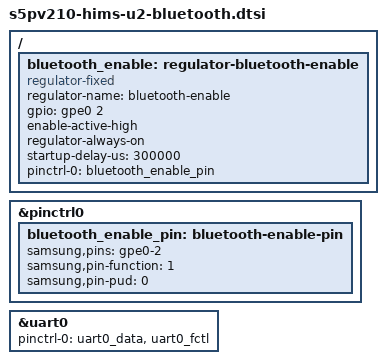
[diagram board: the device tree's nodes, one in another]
// SPDX-License-Identifier: GPL-2.0-only
/* Factory BuiltIn transport: CSR BCSP, COM1/UART0; transport overrides registry baud.
 * HOUSE selector 6 sets GPE0[2] and waits 300 ms. Keep power enabled;
 * suspend, shared factory handshakes and power cycling are not qualified.
 */
/ {
    bluetooth_enable: regulator-bluetooth-enable {
        compatible = "regulator-fixed";
        regulator-name = "bluetooth-enable";
        gpio = <&gpe0 2 GPIO_ACTIVE_HIGH>;
        enable-active-high;
        regulator-always-on;
        startup-delay-us = <300000>;
        pinctrl-names = "default";
        pinctrl-0 = <&bluetooth_enable_pin>;
    };
};
&pinctrl0 {
    bluetooth_enable_pin: bluetooth-enable-pin {
        samsung,pins = "gpe0-2";
        samsung,pin-function = <1>;
        samsung,pin-pud = <0>;
    };
};
&uart0 {
    pinctrl-names = "default";
    pinctrl-0 = <&uart0_data &uart0_fctl>;
    status = "okay";
};
